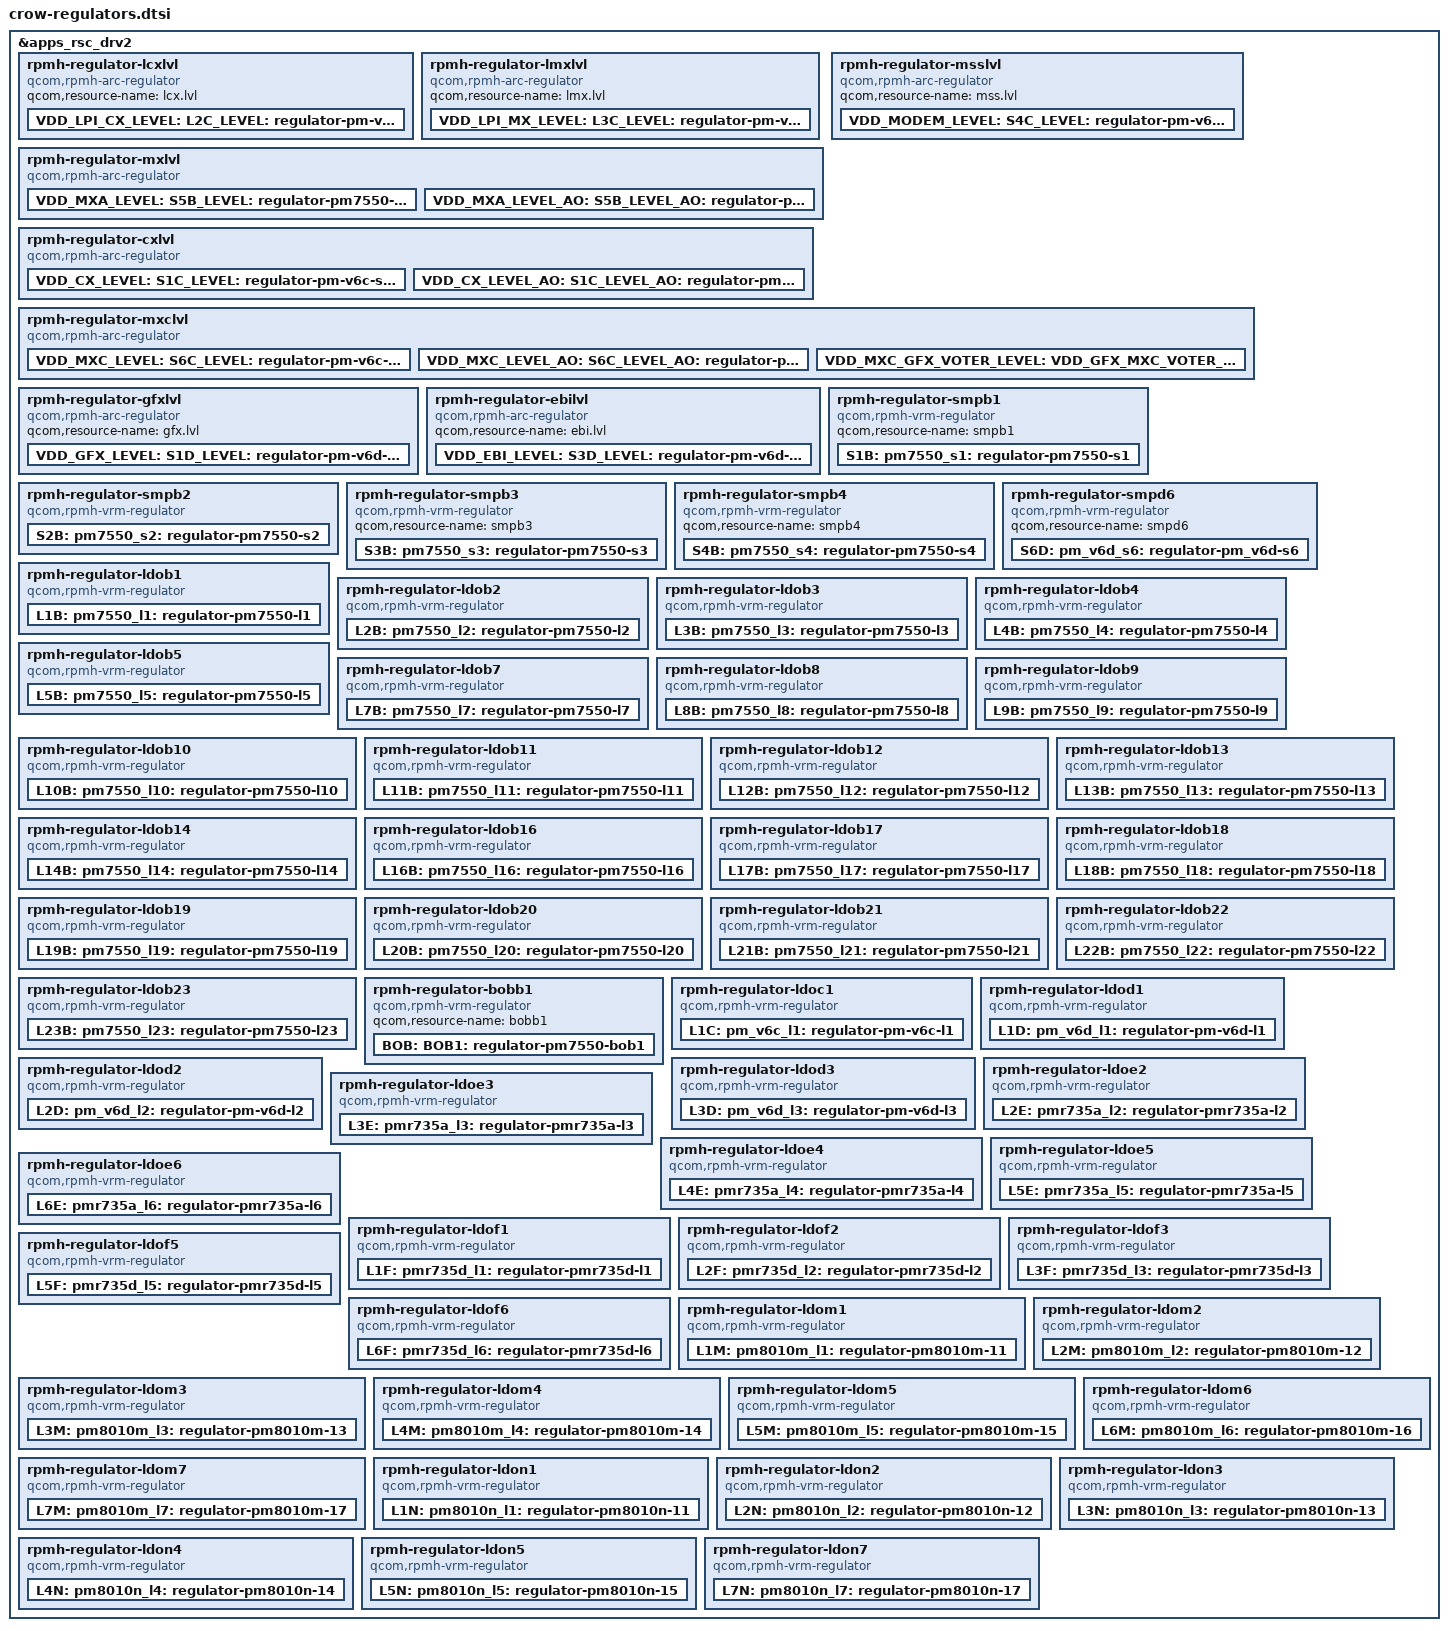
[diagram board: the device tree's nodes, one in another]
#include <dt-bindings/regulator/qcom,rpmh-regulator-levels.h>

&apps_rsc_drv2 {

	rpmh-regulator-lcxlvl {
		compatible = "qcom,rpmh-arc-regulator";
		qcom,resource-name = "lcx.lvl";

		VDD_LPI_CX_LEVEL: L2C_LEVEL:
		pm_v6c_l2_level: regulator-pm-v6c-l2-level {
			regulator-name = "pm_v6c_l2_level";
			qcom,set = <RPMH_REGULATOR_SET_ALL>;
			regulator-min-microvolt =
				<RPMH_REGULATOR_LEVEL_RETENTION>;
			regulator-max-microvolt =
				<RPMH_REGULATOR_LEVEL_MAX>;
			qcom,init-voltage-level =
				<RPMH_REGULATOR_LEVEL_RETENTION>;
		};
	};

	rpmh-regulator-lmxlvl {
		compatible = "qcom,rpmh-arc-regulator";
		qcom,resource-name = "lmx.lvl";

		VDD_LPI_MX_LEVEL: L3C_LEVEL:
		pm_v6c_l3_level: regulator-pm-v6c-l3-level {
			regulator-name = "pm_v6c_l3_level";
			qcom,set = <RPMH_REGULATOR_SET_ALL>;
			regulator-min-microvolt =
				<RPMH_REGULATOR_LEVEL_RETENTION>;
			regulator-max-microvolt =
				<RPMH_REGULATOR_LEVEL_MAX>;
			qcom,init-voltage-level =
				<RPMH_REGULATOR_LEVEL_RETENTION>;
		};
	};

	rpmh-regulator-mxlvl {
		compatible = "qcom,rpmh-arc-regulator";
		qcom,resource-name = "mx.lvl";
		proxy-supply = <&VDD_MXA_LEVEL>;

		VDD_MXA_LEVEL: S5B_LEVEL:
		pm7550_s5_level: regulator-pm7550-s5-level {
			regulator-name = "pm7550_s5_level";
			qcom,set = <RPMH_REGULATOR_SET_ALL>;
			regulator-min-microvolt =
				<RPMH_REGULATOR_LEVEL_RETENTION>;
			regulator-max-microvolt =
				<RPMH_REGULATOR_LEVEL_MAX>;
			qcom,init-voltage-level =
				<RPMH_REGULATOR_LEVEL_TURBO>;
			qcom,proxy-consumer-enable;
			qcom,proxy-consumer-voltage =
				<RPMH_REGULATOR_LEVEL_TURBO
				 RPMH_REGULATOR_LEVEL_MAX>;
		};

		VDD_MXA_LEVEL_AO: S5B_LEVEL_AO:
		pm7550_s5_level_ao: regulator-pm7750-s5-level-ao {
			regulator-name = "pm7550_s5_level_ao";
			qcom,set = <RPMH_REGULATOR_SET_ACTIVE>;
			regulator-min-microvolt =
				<RPMH_REGULATOR_LEVEL_RETENTION>;
			regulator-max-microvolt =
				<RPMH_REGULATOR_LEVEL_MAX>;
			qcom,init-voltage-level =
				<RPMH_REGULATOR_LEVEL_RETENTION>;
		};
	};

	rpmh-regulator-cxlvl {
		compatible = "qcom,rpmh-arc-regulator";
		qcom,resource-name = "cx.lvl";
		proxy-supply = <&VDD_CX_LEVEL>;

		VDD_CX_LEVEL: S1C_LEVEL:
		pm_v6c_s1_level: regulator-pm-v6c-s1-level {
			regulator-name = "pm_v6c_s1_level";
			qcom,set = <RPMH_REGULATOR_SET_ALL>;
			regulator-min-microvolt =
				<RPMH_REGULATOR_LEVEL_RETENTION>;
			regulator-max-microvolt =
				<RPMH_REGULATOR_LEVEL_MAX>;
			qcom,init-voltage-level =
				<RPMH_REGULATOR_LEVEL_TURBO>;
			qcom,proxy-consumer-enable;
			qcom,proxy-consumer-voltage =
				<RPMH_REGULATOR_LEVEL_TURBO
				 RPMH_REGULATOR_LEVEL_MAX>;
		};

		VDD_CX_LEVEL_AO: S1C_LEVEL_AO:
		pm_v6c_s1_level_ao: regulator-pm-v6c-s1-level-ao {
			regulator-name = "pm_v6c_s1_level_ao";
			qcom,set = <RPMH_REGULATOR_SET_ACTIVE>;
			regulator-min-microvolt =
				<RPMH_REGULATOR_LEVEL_RETENTION>;
			regulator-max-microvolt =
				<RPMH_REGULATOR_LEVEL_MAX>;
			qcom,init-voltage-level =
				<RPMH_REGULATOR_LEVEL_RETENTION>;
		};

	};

	rpmh-regulator-msslvl {
		compatible = "qcom,rpmh-arc-regulator";
		qcom,resource-name = "mss.lvl";

		VDD_MODEM_LEVEL: S4C_LEVEL:
		pm_v6c_s4_level: regulator-pm-v6c-s4-level {
			regulator-name = "pm_v6c_s4_level";
			qcom,set = <RPMH_REGULATOR_SET_ALL>;
			regulator-min-microvolt =
				<RPMH_REGULATOR_LEVEL_RETENTION>;
			regulator-max-microvolt =
				<RPMH_REGULATOR_LEVEL_MAX>;
			qcom,init-voltage-level =
				<RPMH_REGULATOR_LEVEL_RETENTION>;
		};
	};

	rpmh-regulator-mxclvl {
		compatible = "qcom,rpmh-arc-regulator";
		qcom,resource-name = "mxc.lvl";
		proxy-supply = <&VDD_MXC_LEVEL>;

		VDD_MXC_LEVEL: S6C_LEVEL:
		pm_v6c_s6_level: regulator-pm-v6c-s6-level {
			regulator-name = "pm_v6c_s6_level";
			qcom,set = <RPMH_REGULATOR_SET_ALL>;
			regulator-min-microvolt =
				<RPMH_REGULATOR_LEVEL_RETENTION>;
			regulator-max-microvolt =
				<RPMH_REGULATOR_LEVEL_MAX>;
			qcom,init-voltage-level =
				<RPMH_REGULATOR_LEVEL_TURBO>;
			qcom,proxy-consumer-enable;
			qcom,proxy-consumer-voltage =
				<RPMH_REGULATOR_LEVEL_TURBO
				 RPMH_REGULATOR_LEVEL_MAX>;
		};

		VDD_MXC_LEVEL_AO: S6C_LEVEL_AO:
		pm_v6c_s6_level_ao: regulator-pm-v6c-s6-level-ao {
			regulator-name = "pm_v6c_s6_level_ao";
			qcom,set = <RPMH_REGULATOR_SET_ACTIVE>;
			regulator-min-microvolt =
				<RPMH_REGULATOR_LEVEL_RETENTION>;
			regulator-max-microvolt =
				<RPMH_REGULATOR_LEVEL_MAX>;
			qcom,init-voltage-level =
				<RPMH_REGULATOR_LEVEL_RETENTION>;
		};

		VDD_MXC_GFX_VOTER_LEVEL: VDD_GFX_MXC_VOTER_LEVEL:
		regulator-pm-v6c-s6-gfx-voter-level {
			regulator-name = "pm_v6c_s6_gfx_voter_level";
			pm_v6c_s6_gfx_voter_level-parent-supply =
				<&VDD_GFX_LEVEL>;
			qcom,set = <RPMH_REGULATOR_SET_ALL>;
			regulator-min-microvolt =
				<RPMH_REGULATOR_LEVEL_MIN_SVS>;
			regulator-max-microvolt =
				<RPMH_REGULATOR_LEVEL_MAX>;
			qcom,init-voltage-level =
				<RPMH_REGULATOR_LEVEL_MIN_SVS>;
		};


	};

	rpmh-regulator-gfxlvl {
		compatible = "qcom,rpmh-arc-regulator";
		qcom,resource-name = "gfx.lvl";

		VDD_GFX_LEVEL: S1D_LEVEL:
		pm_v6d_s1_level: regulator-pm-v6d-s1-level {
			regulator-name = "pm_v6d_s1_level";
			qcom,set = <RPMH_REGULATOR_SET_ALL>;
			regulator-min-microvolt =
				<RPMH_REGULATOR_LEVEL_RETENTION>;
			regulator-max-microvolt =
				<RPMH_REGULATOR_LEVEL_MAX>;
			qcom,init-voltage-level =
				<RPMH_REGULATOR_LEVEL_RETENTION>;
		};
	};

	rpmh-regulator-ebilvl {
		compatible = "qcom,rpmh-arc-regulator";
		qcom,resource-name = "ebi.lvl";

		VDD_EBI_LEVEL: S3D_LEVEL:
		pm_v6d_s3_level: regulator-pm-v6d-s3-level {
			regulator-name = "pm_v6d_s3_level";
			qcom,set = <RPMH_REGULATOR_SET_ALL>;
			regulator-min-microvolt =
				<RPMH_REGULATOR_LEVEL_RETENTION>;
			regulator-max-microvolt =
				<RPMH_REGULATOR_LEVEL_MAX>;
			qcom,init-voltage-level =
				<RPMH_REGULATOR_LEVEL_RETENTION>;
		};
	};

	rpmh-regulator-smpb1 {
		compatible = "qcom,rpmh-vrm-regulator";
		qcom,resource-name = "smpb1";
		S1B: pm7550_s1: regulator-pm7550-s1 {
			regulator-name = "pm7550_s1";
			qcom,set = <RPMH_REGULATOR_SET_ALL>;
			regulator-min-microvolt = <1800000>;
			regulator-max-microvolt = <2040000>;
			qcom,init-voltage = <1872000>;
		};
	};

	rpmh-regulator-smpb2 {
		compatible = "qcom,rpmh-vrm-regulator";
		qcom,resource-name = "smpb2";
		qcom,regulator-type = "pmic5-ftsmps";
		qcom,supported-modes =
			<RPMH_REGULATOR_MODE_RET
			RPMH_REGULATOR_MODE_HPM>;
		qcom,mode-threshold-currents = <0 200000>;

		S2B: pm7550_s2: regulator-pm7550-s2 {
			regulator-name = "pm7550_s2";
			qcom,set = <RPMH_REGULATOR_SET_ALL>;
			regulator-min-microvolt = <1256000>;
			regulator-max-microvolt = <1408000>;
			qcom,init-voltage = <1304000>;
			qcom,init-mode = <RPMH_REGULATOR_MODE_RET>;
		};
	};

	rpmh-regulator-smpb3 {
		compatible = "qcom,rpmh-vrm-regulator";
		qcom,resource-name = "smpb3";
		S3B: pm7550_s3: regulator-pm7550-s3 {
			regulator-name = "pm7550_s3";
			qcom,set = <RPMH_REGULATOR_SET_ALL>;
			regulator-min-microvolt = <880000>;
			regulator-max-microvolt = <1040000>;
			qcom,init-voltage = <972000>;
		};
	};

	rpmh-regulator-smpb4 {
		compatible = "qcom,rpmh-vrm-regulator";
		qcom,resource-name = "smpb4";
		S4B: pm7550_s4: regulator-pm7550-s4 {
			regulator-name = "pm7550_s4";
			qcom,set = <RPMH_REGULATOR_SET_ALL>;
			regulator-min-microvolt = <2200000>;
			regulator-max-microvolt = <2200000>;
			qcom,init-voltage = <2200000>;
		};
	};

	rpmh-regulator-smpd6 {
		compatible = "qcom,rpmh-vrm-regulator";
		qcom,resource-name = "smpd6";
		S6D: pm_v6d_s6: regulator-pm_v6d-s6 {
			regulator-name = "pm_v6d_s6";
			qcom,set = <RPMH_REGULATOR_SET_ALL>;
			regulator-min-microvolt = <1010000>;
			regulator-max-microvolt = <1170000>;
			qcom,init-voltage = <1010000>;
		};
	};

	rpmh-regulator-ldob1 {
		compatible = "qcom,rpmh-vrm-regulator";
		qcom,resource-name = "ldob1";
		qcom,regulator-type = "pmic5-ldo";
		qcom,supported-modes =
			<RPMH_REGULATOR_MODE_LPM
			RPMH_REGULATOR_MODE_HPM>;
		qcom,mode-threshold-currents = <0 30000>;
		L1B:
		pm7550_l1: regulator-pm7550-l1 {
			regulator-name = "pm7550_l1";
			qcom,set = <RPMH_REGULATOR_SET_ALL>;
			regulator-min-microvolt = <880000>;
			regulator-max-microvolt = <912000>;
			qcom,init-voltage = <880000>;
			qcom,init-mode = <RPMH_REGULATOR_MODE_HPM>;
		};
	};

	rpmh-regulator-ldob2 {
		compatible = "qcom,rpmh-vrm-regulator";
		qcom,resource-name = "ldob2";
		qcom,regulator-type = "pmic5-ldo";
		qcom,supported-modes =
			<RPMH_REGULATOR_MODE_LPM
			RPMH_REGULATOR_MODE_HPM>;
		qcom,mode-threshold-currents = <0 30000>;
		proxy-supply = <&L2B>;

		L2B:
		pm7550_l2: regulator-pm7550-l2 {
			regulator-name = "pm7550_l2";
			qcom,set = <RPMH_REGULATOR_SET_ALL>;
			regulator-min-microvolt = <880000>;
			regulator-max-microvolt = <912000>;
			qcom,init-voltage = <880000>;
			qcom,init-mode = <RPMH_REGULATOR_MODE_HPM>;
			qcom,proxy-consumer-enable;
			qcom,proxy-consumer-current = <98400>;
		};
	};

	rpmh-regulator-ldob3 {
		compatible = "qcom,rpmh-vrm-regulator";
		qcom,resource-name = "ldob3";
		qcom,regulator-type = "pmic5-ldo";
		qcom,supported-modes =
			<RPMH_REGULATOR_MODE_LPM
			RPMH_REGULATOR_MODE_HPM>;
		qcom,mode-threshold-currents = <0 30000>;
		L3B:
		pm7550_l3: regulator-pm7550-l3 {
			regulator-name = "pm7550_l3";
			qcom,set = <RPMH_REGULATOR_SET_ALL>;
			regulator-min-microvolt = <880000>;
			regulator-max-microvolt = <912000>;
			qcom,init-voltage = <880000>;
			qcom,init-mode = <RPMH_REGULATOR_MODE_HPM>;
		};
	};

	rpmh-regulator-ldob4 {
		compatible = "qcom,rpmh-vrm-regulator";
		qcom,resource-name = "ldob4";
		qcom,regulator-type = "pmic5-ldo";
		qcom,supported-modes =
			<RPMH_REGULATOR_MODE_LPM
			RPMH_REGULATOR_MODE_HPM>;
		qcom,mode-threshold-currents = <0 30000>;
		proxy-supply = <&L4B>;

		L4B:
		pm7550_l4: regulator-pm7550-l4 {
			regulator-name = "pm7550_l4";
			qcom,set = <RPMH_REGULATOR_SET_ALL>;
			regulator-min-microvolt = <1200000>;
			regulator-max-microvolt = <1200000>;
			qcom,init-voltage = <1200000>;
			qcom,init-mode = <RPMH_REGULATOR_MODE_HPM>;
			qcom,proxy-consumer-enable;
			qcom,proxy-consumer-current = <16800>;
		};
	};

	rpmh-regulator-ldob5 {
		compatible = "qcom,rpmh-vrm-regulator";
		qcom,resource-name = "ldob5";
		qcom,regulator-type = "pmic5-ldo";
		qcom,supported-modes =
			<RPMH_REGULATOR_MODE_RET
			RPMH_REGULATOR_MODE_LPM
			RPMH_REGULATOR_MODE_HPM>;
		qcom,mode-threshold-currents = <0 10000 30000>;
		L5B:
		pm7550_l5: regulator-pm7550-l5 {
			regulator-name = "pm7550_l5";
			qcom,set = <RPMH_REGULATOR_SET_ALL>;
			regulator-min-microvolt = <1200000>;
			regulator-max-microvolt = <1200000>;
			qcom,init-voltage = <1200000>;
			qcom,init-mode = <RPMH_REGULATOR_MODE_HPM>;
		};
	};

	rpmh-regulator-ldob7 {
		compatible = "qcom,rpmh-vrm-regulator";
		qcom,resource-name = "ldob7";
		qcom,regulator-type = "pmic5-ldo";
		qcom,supported-modes =
			<RPMH_REGULATOR_MODE_LPM
			RPMH_REGULATOR_MODE_HPM>;
		qcom,mode-threshold-currents = <0 30000>;
		L7B:
		pm7550_l7: regulator-pm7550-l7 {
			regulator-name = "pm7550_l7";
			qcom,set = <RPMH_REGULATOR_SET_ALL>;
			regulator-min-microvolt = <1800000>;
			regulator-max-microvolt = <1800000>;
			qcom,init-voltage = <1800000>;
			qcom,init-mode = <RPMH_REGULATOR_MODE_HPM>;
		};
	};

	rpmh-regulator-ldob8 {
		compatible = "qcom,rpmh-vrm-regulator";
		qcom,resource-name = "ldob8";
		qcom,regulator-type = "pmic5-ldo";
		qcom,supported-modes =
			<RPMH_REGULATOR_MODE_LPM
			RPMH_REGULATOR_MODE_HPM>;
		qcom,mode-threshold-currents = <0 30000>;
		L8B:
		pm7550_l8: regulator-pm7550-l8 {
			regulator-name = "pm7550_l8";
			qcom,set = <RPMH_REGULATOR_SET_ALL>;
			regulator-min-microvolt = <1800000>;
			regulator-max-microvolt = <1800000>;
			qcom,init-voltage = <1800000>;
			qcom,init-mode = <RPMH_REGULATOR_MODE_HPM>;
		};
	};

	rpmh-regulator-ldob9 {
		compatible = "qcom,rpmh-vrm-regulator";
		qcom,resource-name = "ldob9";
		qcom,regulator-type = "pmic5-ldo";
		qcom,supported-modes =
			<RPMH_REGULATOR_MODE_LPM
			RPMH_REGULATOR_MODE_HPM>;
		qcom,mode-threshold-currents = <0 30000>;
		proxy-supply = <&L9B>;

		L9B:
		pm7550_l9: regulator-pm7550-l9 {
			regulator-name = "pm7550_l9";
			qcom,set = <RPMH_REGULATOR_SET_ALL>;
			regulator-min-microvolt = <1800000>;
			regulator-max-microvolt = <1800000>;
			qcom,init-voltage = <1800000>;
			qcom,init-mode = <RPMH_REGULATOR_MODE_HPM>;
			qcom,proxy-consumer-enable;
			qcom,proxy-consumer-current = <200000>;
		};
	};

	rpmh-regulator-ldob10 {
		compatible = "qcom,rpmh-vrm-regulator";
		qcom,resource-name = "ldob10";
		qcom,regulator-type = "pmic5-ldo";
		qcom,supported-modes =
			<RPMH_REGULATOR_MODE_LPM
			RPMH_REGULATOR_MODE_HPM>;
		qcom,mode-threshold-currents = <0 30000>;
		L10B:
		pm7550_l10: regulator-pm7550-l10 {
			regulator-name = "pm7550_l10";
			qcom,set = <RPMH_REGULATOR_SET_ALL>;
			regulator-min-microvolt = <1800000>;
			regulator-max-microvolt = <1800000>;
			qcom,init-voltage = <1800000>;
			qcom,init-mode = <RPMH_REGULATOR_MODE_HPM>;
		};
	};

	rpmh-regulator-ldob11 {
		compatible = "qcom,rpmh-vrm-regulator";
		qcom,resource-name = "ldob11";
		qcom,regulator-type = "pmic5-ldo";
		qcom,supported-modes =
			<RPMH_REGULATOR_MODE_LPM
			RPMH_REGULATOR_MODE_HPM>;
		qcom,mode-threshold-currents = <0 30000>;
		L11B:
		pm7550_l11: regulator-pm7550-l11 {
			regulator-name = "pm7550_l11";
			qcom,set = <RPMH_REGULATOR_SET_ALL>;
			regulator-min-microvolt = <1800000>;
			regulator-max-microvolt = <1800000>;
			qcom,init-voltage = <1800000>;
			qcom,init-mode = <RPMH_REGULATOR_MODE_HPM>;
		};
	};

	rpmh-regulator-ldob12 {
		compatible = "qcom,rpmh-vrm-regulator";
		qcom,resource-name = "ldob12";
		qcom,regulator-type = "pmic5-ldo";
		qcom,supported-modes =
			<RPMH_REGULATOR_MODE_LPM
			RPMH_REGULATOR_MODE_HPM>;
		qcom,mode-threshold-currents = <0 10000>;
		/*This is for UFS Peripheral,which supports 2 variants*/
		/*UFS 3.1 ,and UFS 2.2 both require different voltages.*/
		/* Hence Not providing voltage values as per previous targets*/
		L12B:
		pm7550_l12: regulator-pm7550-l12 {
			regulator-name = "pm7550_l12";
			qcom,set = <RPMH_REGULATOR_SET_ALL>;
			qcom,init-mode = <RPMH_REGULATOR_MODE_HPM>;
		};
	};

	rpmh-regulator-ldob13 {
		compatible = "qcom,rpmh-vrm-regulator";
		qcom,resource-name = "ldob13";
		qcom,regulator-type = "pmic5-ldo";
		qcom,supported-modes =
			<RPMH_REGULATOR_MODE_LPM
			RPMH_REGULATOR_MODE_HPM>;
		qcom,mode-threshold-currents = <0 10000>;
		L13B:
		pm7550_l13: regulator-pm7550-l13 {
			regulator-name = "pm7550_l13";
			qcom,set = <RPMH_REGULATOR_SET_ALL>;
			regulator-min-microvolt = <2700000>;
			regulator-max-microvolt = <3300000>;
			qcom,init-voltage = <2700000>;
			qcom,init-mode = <RPMH_REGULATOR_MODE_HPM>;
		};
	};

	rpmh-regulator-ldob14 {
		compatible = "qcom,rpmh-vrm-regulator";
		qcom,resource-name = "ldob14";
		qcom,regulator-type = "pmic5-ldo";
		qcom,supported-modes =
			<RPMH_REGULATOR_MODE_LPM
			RPMH_REGULATOR_MODE_HPM>;
		qcom,mode-threshold-currents = <0 10000>;
		L14B:
		pm7550_l14: regulator-pm7550-l14 {
			regulator-name = "pm7550_l14";
			qcom,set = <RPMH_REGULATOR_SET_ALL>;
			regulator-min-microvolt = <2650000>;
			regulator-max-microvolt = <2940000>;
			qcom,init-voltage = <2650000>;
			qcom,init-mode = <RPMH_REGULATOR_MODE_HPM>;
		};
	};

	rpmh-regulator-ldob16 {
		compatible = "qcom,rpmh-vrm-regulator";
		qcom,resource-name = "ldob16";
		qcom,regulator-type = "pmic5-ldo";
		qcom,supported-modes =
			<RPMH_REGULATOR_MODE_LPM
			RPMH_REGULATOR_MODE_HPM>;
		qcom,mode-threshold-currents = <0 10000>;
		L16B:
		pm7550_l16: regulator-pm7550-l16 {
			regulator-name = "pm7550_l16";
			qcom,set = <RPMH_REGULATOR_SET_ALL>;
			regulator-min-microvolt = <3008000>;
			regulator-max-microvolt = <3008000>;
			qcom,init-voltage = <3008000>;
			qcom,init-mode = <RPMH_REGULATOR_MODE_HPM>;
		};
	};

	rpmh-regulator-ldob17 {
		compatible = "qcom,rpmh-vrm-regulator";
		qcom,resource-name = "ldob17";
		qcom,regulator-type = "pmic5-ldo";
		qcom,supported-modes =
			<RPMH_REGULATOR_MODE_LPM
			RPMH_REGULATOR_MODE_HPM>;
		qcom,mode-threshold-currents = <0 10000>;
		L17B:
		pm7550_l17: regulator-pm7550-l17 {
			regulator-name = "pm7550_l17";
			qcom,set = <RPMH_REGULATOR_SET_ALL>;
			regulator-min-microvolt = <3104000>;
			regulator-max-microvolt = <3104000>;
			qcom,init-voltage = <3104000>;
			qcom,init-mode = <RPMH_REGULATOR_MODE_HPM>;
		};
	};

	rpmh-regulator-ldob18 {
		compatible = "qcom,rpmh-vrm-regulator";
		qcom,resource-name = "ldob18";
		qcom,regulator-type = "pmic5-ldo";
		qcom,supported-modes =
			<RPMH_REGULATOR_MODE_LPM
			RPMH_REGULATOR_MODE_HPM>;
		qcom,mode-threshold-currents = <0 10000>;
		L18B:
		pm7550_l18: regulator-pm7550-l18 {
			regulator-name = "pm7550_l18";
			qcom,set = <RPMH_REGULATOR_SET_ALL>;
			regulator-min-microvolt = <2800000>;
			regulator-max-microvolt = <2800000>;
			qcom,init-voltage = <2800000>;
			qcom,init-mode = <RPMH_REGULATOR_MODE_HPM>;
		};
	};

	rpmh-regulator-ldob19 {
		compatible = "qcom,rpmh-vrm-regulator";
		qcom,resource-name = "ldob19";
		qcom,regulator-type = "pmic5-ldo";
		qcom,supported-modes =
			<RPMH_REGULATOR_MODE_LPM
			RPMH_REGULATOR_MODE_HPM>;
		qcom,mode-threshold-currents = <0 10000>;
		proxy-supply = <&L19B>;

		L19B:
		pm7550_l19: regulator-pm7550-l19 {
			regulator-name = "pm7550_l19";
			qcom,set = <RPMH_REGULATOR_SET_ALL>;
			regulator-min-microvolt = <3000000>;
			regulator-max-microvolt = <3000000>;
			qcom,init-voltage = <3000000>;
			qcom,init-mode = <RPMH_REGULATOR_MODE_HPM>;
			qcom,proxy-consumer-enable;
			qcom,proxy-consumer-current = <10000>;
		};
	};

	rpmh-regulator-ldob20 {
		compatible = "qcom,rpmh-vrm-regulator";
		qcom,resource-name = "ldob20";
		qcom,regulator-type = "pmic5-ldo";
		qcom,supported-modes =
			<RPMH_REGULATOR_MODE_LPM
			RPMH_REGULATOR_MODE_HPM>;
		qcom,mode-threshold-currents = <0 10000>;
		L20B:
		pm7550_l20: regulator-pm7550-l20 {
			regulator-name = "pm7550_l20";
			qcom,set = <RPMH_REGULATOR_SET_ALL>;
			regulator-min-microvolt = <1620000>;
			regulator-max-microvolt = <3544000>;
			qcom,init-voltage = <1620000>;
			qcom,init-mode = <RPMH_REGULATOR_MODE_HPM>;
		};
	};

	rpmh-regulator-ldob21 {
		compatible = "qcom,rpmh-vrm-regulator";
		qcom,resource-name = "ldob21";
		qcom,regulator-type = "pmic5-ldo";
		qcom,supported-modes =
			<RPMH_REGULATOR_MODE_LPM
			RPMH_REGULATOR_MODE_HPM>;
		qcom,mode-threshold-currents = <0 10000>;
		L21B:
		pm7550_l21: regulator-pm7550-l21 {
			regulator-name = "pm7550_l21";
			qcom,set = <RPMH_REGULATOR_SET_ALL>;
			regulator-min-microvolt = <1620000>;
			regulator-max-microvolt = <3544000>;
			qcom,init-voltage = <1620000>;
			qcom,init-mode = <RPMH_REGULATOR_MODE_HPM>;
		};
	};

	rpmh-regulator-ldob22 {
		compatible = "qcom,rpmh-vrm-regulator";
		qcom,resource-name = "ldob22";
		qcom,regulator-type = "pmic5-ldo";
		qcom,supported-modes =
			<RPMH_REGULATOR_MODE_LPM
			RPMH_REGULATOR_MODE_HPM>;
		qcom,mode-threshold-currents = <0 10000>;
		L22B:
		pm7550_l22: regulator-pm7550-l22 {
			regulator-name = "pm7550_l22";
			qcom,set = <RPMH_REGULATOR_SET_ALL>;
			regulator-min-microvolt = <3200000>;
			regulator-max-microvolt = <3200000>;
			qcom,init-voltage = <3200000>;
			qcom,init-mode = <RPMH_REGULATOR_MODE_HPM>;
		};
	};

	rpmh-regulator-ldob23 {
		compatible = "qcom,rpmh-vrm-regulator";
		qcom,resource-name = "ldob23";
		qcom,regulator-type = "pmic5-ldo";
		qcom,supported-modes =
			<RPMH_REGULATOR_MODE_LPM
			RPMH_REGULATOR_MODE_HPM>;
		qcom,mode-threshold-currents = <0 10000>;
		L23B:
		pm7550_l23: regulator-pm7550-l23 {
			regulator-name = "pm7550_l23";
			qcom,set = <RPMH_REGULATOR_SET_ALL>;
			regulator-min-microvolt = <1650000>;
			regulator-max-microvolt = <3544000>;
			qcom,init-voltage = <1650000>;
			qcom,init-mode = <RPMH_REGULATOR_MODE_HPM>;
		};
	};

	rpmh-regulator-bobb1 {
		compatible = "qcom,rpmh-vrm-regulator";
		qcom,resource-name = "bobb1";

		BOB:
		BOB1:
		pm7550_bob1: regulator-pm7550-bob1 {
			regulator-name = "pm7550_bob1";
			qcom,set = <RPMH_REGULATOR_SET_ALL>;
			regulator-min-microvolt = <3008000>;
			regulator-max-microvolt = <3960000>;
			qcom,init-voltage = <3296000>;
		};
	};

	rpmh-regulator-ldoc1 {
		compatible = "qcom,rpmh-vrm-regulator";
		qcom,resource-name = "ldoc1";
		qcom,regulator-type = "pmic5-ldo";
		qcom,supported-modes =
			<RPMH_REGULATOR_MODE_LPM
			RPMH_REGULATOR_MODE_HPM>;
		qcom,mode-threshold-currents = <0 30000>;
		L1C:
		pm_v6c_l1: regulator-pm-v6c-l1 {
			regulator-name = "pm_v6c_l1";
			qcom,set = <RPMH_REGULATOR_SET_ALL>;
			regulator-min-microvolt = <320000>;
			regulator-max-microvolt = <650000>;
			qcom,init-voltage = <300000>;
			qcom,init-mode = <RPMH_REGULATOR_MODE_HPM>;
		};
	};

	rpmh-regulator-ldod1 {
		compatible = "qcom,rpmh-vrm-regulator";
		qcom,resource-name = "ldod1";
		qcom,regulator-type = "pmic5-ldo";
		qcom,supported-modes =
			<RPMH_REGULATOR_MODE_LPM
			 RPMH_REGULATOR_MODE_HPM>;
		qcom,mode-threshold-currents = <0 30000>;

		L1D:
		pm_v6d_l1: regulator-pm-v6d-l1 {
			regulator-name = "pm_v6d_l1";
			qcom,set = <RPMH_REGULATOR_SET_ALL>;
			regulator-min-microvolt = <870000>;
			regulator-max-microvolt = <970000>;
			qcom,init-voltage = <904000>;
			qcom,init-mode = <RPMH_REGULATOR_MODE_HPM>;
		};
	};

	rpmh-regulator-ldod2 {
		compatible = "qcom,rpmh-vrm-regulator";
		qcom,resource-name = "ldod2";
		qcom,regulator-type = "pmic5-ldo";
		qcom,supported-modes =
			<RPMH_REGULATOR_MODE_LPM
			 RPMH_REGULATOR_MODE_HPM>;
		qcom,mode-threshold-currents = <0 30000>;

		/*This is for UFS Peripheral,which supports 2 variants*/
		/*UFS 3.1 ,and UFS 2.2 both require different voltages.*/
		/* Hence Not providing voltage values as per previous targets*/
		L2D:
		pm_v6d_l2: regulator-pm-v6d-l2 {
			regulator-name = "pm_v6d_l2";
			qcom,set = <RPMH_REGULATOR_SET_ALL>;
			qcom,init-mode = <RPMH_REGULATOR_MODE_HPM>;
		};
	};

	rpmh-regulator-ldod3 {
		compatible = "qcom,rpmh-vrm-regulator";
		qcom,resource-name = "ldod3";
		qcom,regulator-type = "pmic5-ldo";
		qcom,supported-modes =
			<RPMH_REGULATOR_MODE_LPM
			 RPMH_REGULATOR_MODE_HPM>;
		qcom,mode-threshold-currents = <0 30000>;
		proxy-supply = <&L3D>;

		L3D:
		pm_v6d_l3: regulator-pm-v6d-l3 {
			regulator-name = "pm_v6d_l3";
			qcom,set = <RPMH_REGULATOR_SET_ALL>;
			regulator-min-microvolt = <1200000>;
			regulator-max-microvolt = <1200000>;
			qcom,init-voltage = <1200000>;
			qcom,init-mode = <RPMH_REGULATOR_MODE_HPM>;
			qcom,proxy-consumer-enable;
			qcom,proxy-consumer-current = <299000>;
		};
	};

	rpmh-regulator-ldoe2 {
		compatible = "qcom,rpmh-vrm-regulator";
		qcom,resource-name = "ldoe2";
		qcom,regulator-type = "pmic5-ldo";
		qcom,supported-modes =
			<RPMH_REGULATOR_MODE_LPM
			 RPMH_REGULATOR_MODE_HPM>;
		qcom,mode-threshold-currents = <0 30000>;
		L2E:
		pmr735a_l2: regulator-pmr735a-l2 {
			regulator-name = "pmr735a_l2";
			qcom,set = <RPMH_REGULATOR_SET_ALL>;
			regulator-min-microvolt = <800000>;
			regulator-max-microvolt = <800000>;
			qcom,init-voltage = <800000>;
			qcom,init-mode = <RPMH_REGULATOR_MODE_HPM>;
		};
	};

	rpmh-regulator-ldoe3 {
		compatible = "qcom,rpmh-vrm-regulator";
		qcom,resource-name = "ldoe3";
		qcom,regulator-type = "pmic5-ldo";
		qcom,supported-modes =
			<RPMH_REGULATOR_MODE_LPM
			 RPMH_REGULATOR_MODE_HPM>;
		qcom,mode-threshold-currents = <0 30000>;
		L3E:
		pmr735a_l3: regulator-pmr735a-l3 {
			regulator-name = "pmr735a_l3";
			qcom,set = <RPMH_REGULATOR_SET_ALL>;
			regulator-min-microvolt = <588000>;
			regulator-max-microvolt = <800000>;
			qcom,init-voltage = <588000>;
			qcom,init-mode = <RPMH_REGULATOR_MODE_HPM>;
		};
	};

	rpmh-regulator-ldoe4 {
		compatible = "qcom,rpmh-vrm-regulator";
		qcom,resource-name = "ldoe4";
		qcom,regulator-type = "pmic5-ldo";
		qcom,supported-modes =
			<RPMH_REGULATOR_MODE_LPM
			 RPMH_REGULATOR_MODE_HPM>;
		qcom,mode-threshold-currents = <0 10000>;
		L4E:
		pmr735a_l4: regulator-pmr735a-l4 {
			regulator-name = "pmr735a_l4";
			qcom,set = <RPMH_REGULATOR_SET_ALL>;
			regulator-min-microvolt = <1776000>;
			regulator-max-microvolt = <1776000>;
			qcom,init-voltage = <1776000>;
			qcom,init-mode = <RPMH_REGULATOR_MODE_HPM>;
		};
	};

	rpmh-regulator-ldoe5 {
		compatible = "qcom,rpmh-vrm-regulator";
		qcom,resource-name = "ldoe5";
		qcom,regulator-type = "pmic5-ldo";
		qcom,supported-modes =
			<RPMH_REGULATOR_MODE_LPM
			 RPMH_REGULATOR_MODE_HPM>;
		qcom,mode-threshold-currents = <0 30000>;
		L5E:
		pmr735a_l5: regulator-pmr735a-l5 {
			regulator-name = "pmr735a_l5";
			qcom,set = <RPMH_REGULATOR_SET_ALL>;
			regulator-min-microvolt = <1200000>;
			regulator-max-microvolt = <1200000>;
			qcom,init-voltage = <1200000>;
			qcom,init-mode = <RPMH_REGULATOR_MODE_HPM>;
		};
	};

	rpmh-regulator-ldoe6 {
		compatible = "qcom,rpmh-vrm-regulator";
		qcom,resource-name = "ldoe6";
		qcom,regulator-type = "pmic5-ldo";
		qcom,supported-modes =
			<RPMH_REGULATOR_MODE_LPM
			 RPMH_REGULATOR_MODE_HPM>;
		qcom,mode-threshold-currents = <0 30000>;
		L6E:
		pmr735a_l6: regulator-pmr735a-l6 {
			regulator-name = "pmr735a_l6";
			qcom,set = <RPMH_REGULATOR_SET_ALL>;
			regulator-min-microvolt = <880000>;
			regulator-max-microvolt = <912000>;
			qcom,init-voltage = <880000>;
			qcom,init-mode = <RPMH_REGULATOR_MODE_HPM>;
		};
	};

	rpmh-regulator-ldof1 {
		compatible = "qcom,rpmh-vrm-regulator";
		qcom,resource-name = "ldof1";
		qcom,regulator-type = "pmic5-ldo";
		qcom,supported-modes =
			<RPMH_REGULATOR_MODE_LPM
			 RPMH_REGULATOR_MODE_HPM>;
		qcom,mode-threshold-currents = <0 30000>;
		L1F:
		pmr735d_l1: regulator-pmr735d-l1 {
			regulator-name = "pmr735d_l1";
			qcom,set = <RPMH_REGULATOR_SET_ALL>;
			regulator-min-microvolt = <852000>;
			regulator-max-microvolt = <950000>;
			qcom,init-voltage = <852000>;
			qcom,init-mode = <RPMH_REGULATOR_MODE_HPM>;
		};
	};

	rpmh-regulator-ldof2 {
		compatible = "qcom,rpmh-vrm-regulator";
		qcom,resource-name = "ldof2";
		qcom,regulator-type = "pmic5-ldo";
		qcom,supported-modes =
			<RPMH_REGULATOR_MODE_LPM
			 RPMH_REGULATOR_MODE_HPM>;
		qcom,mode-threshold-currents = <0 30000>;
		L2F:
		pmr735d_l2: regulator-pmr735d-l2 {
			regulator-name = "pmr735d_l2";
			qcom,set = <RPMH_REGULATOR_SET_ALL>;
			regulator-min-microvolt = <320000>;
			regulator-max-microvolt = <864000>;
			qcom,init-voltage = <304000>;
			qcom,init-mode = <RPMH_REGULATOR_MODE_HPM>;
		};
	};

	rpmh-regulator-ldof3 {
		compatible = "qcom,rpmh-vrm-regulator";
		qcom,resource-name = "ldof3";
		qcom,regulator-type = "pmic5-ldo";
		qcom,supported-modes =
			<RPMH_REGULATOR_MODE_LPM
			 RPMH_REGULATOR_MODE_HPM>;
		qcom,mode-threshold-currents = <0 30000>;
		L3F:
		pmr735d_l3: regulator-pmr735d-l3 {
			regulator-name = "pmr735d_l3";
			qcom,set = <RPMH_REGULATOR_SET_ALL>;
			regulator-min-microvolt = <1080000>;
			regulator-max-microvolt = <1350000>;
			qcom,init-voltage = <108000>;
			qcom,init-mode = <RPMH_REGULATOR_MODE_HPM>;
		};
	};

	rpmh-regulator-ldof5 {
		compatible = "qcom,rpmh-vrm-regulator";
		qcom,resource-name = "ldof5";
		qcom,regulator-type = "pmic5-ldo";
		qcom,supported-modes =
			<RPMH_REGULATOR_MODE_LPM
			 RPMH_REGULATOR_MODE_HPM>;
		qcom,mode-threshold-currents = <0 30000>;
		L5F:
		pmr735d_l5: regulator-pmr735d-l5 {
			regulator-name = "pmr735d_l5";
			qcom,set = <RPMH_REGULATOR_SET_ALL>;
			regulator-min-microvolt = <751000>;
			regulator-max-microvolt = <824000>;
			qcom,init-voltage = <751000>;
			qcom,init-mode = <RPMH_REGULATOR_MODE_HPM>;
		};
	};

	rpmh-regulator-ldof6 {
		compatible = "qcom,rpmh-vrm-regulator";
		qcom,resource-name = "ldof6";
		qcom,regulator-type = "pmic5-ldo";
		qcom,supported-modes =
			<RPMH_REGULATOR_MODE_LPM
			 RPMH_REGULATOR_MODE_HPM>;
		qcom,mode-threshold-currents = <0 30000>;
		L6F:
		pmr735d_l6: regulator-pmr735d-l6 {
			regulator-name = "pmr735d_l6";
			qcom,set = <RPMH_REGULATOR_SET_ALL>;
			regulator-min-microvolt = <1500000>;
			regulator-max-microvolt = <1800000>;
			qcom,init-voltage = <1500000>;
			qcom,init-mode = <RPMH_REGULATOR_MODE_HPM>;
		};
	};

	rpmh-regulator-ldom1 {
		compatible = "qcom,rpmh-vrm-regulator";
		qcom,resource-name = "ldom1";
		qcom,regulator-type = "pmic5-ldo";
		qcom,supported-modes =
			<RPMH_REGULATOR_MODE_LPM
			 RPMH_REGULATOR_MODE_HPM>;
		qcom,mode-threshold-currents = <0 30000>;

		L1M:
		pm8010m_l1: regulator-pm8010m-11 {
			regulator-name = "pm8010m_l1";
			qcom,set = <RPMH_REGULATOR_SET_ALL>;
			regulator-min-microvolt = <1050000>;
			regulator-max-microvolt = <1180000>;
			qcom,init-voltage = <1050000>;
			qcom,init-mode = <RPMH_REGULATOR_MODE_HPM>;
		};
	};

	rpmh-regulator-ldom2 {
		compatible = "qcom,rpmh-vrm-regulator";
		qcom,resource-name = "ldom2";
		qcom,regulator-type = "pmic5-ldo";
		qcom,supported-modes =
			<RPMH_REGULATOR_MODE_LPM
			 RPMH_REGULATOR_MODE_HPM>;
		qcom,mode-threshold-currents = <0 30000>;

		L2M:
		pm8010m_l2: regulator-pm8010m-12 {
			regulator-name = "pm8010m_l2";
			qcom,set = <RPMH_REGULATOR_SET_ALL>;
			regulator-min-microvolt = <950000>;
			regulator-max-microvolt = <1150000>;
			qcom,init-voltage = <950000>;
			qcom,init-mode = <RPMH_REGULATOR_MODE_HPM>;
		};
	};

	rpmh-regulator-ldom3 {
		compatible = "qcom,rpmh-vrm-regulator";
		qcom,resource-name = "ldom3";
		qcom,regulator-type = "pmic5-ldo";
		qcom,supported-modes =
			<RPMH_REGULATOR_MODE_LPM
			 RPMH_REGULATOR_MODE_HPM>;
		qcom,mode-threshold-currents = <0 10000>;

		L3M:
		pm8010m_l3: regulator-pm8010m-13 {
			regulator-name = "pm8010m_l3";
			qcom,set = <RPMH_REGULATOR_SET_ALL>;
			regulator-min-microvolt = <2700000>;
			regulator-max-microvolt = <2900000>;
			qcom,init-voltage = <2700000>;
			qcom,init-mode = <RPMH_REGULATOR_MODE_HPM>;
		};
	};

	rpmh-regulator-ldom4 {
		compatible = "qcom,rpmh-vrm-regulator";
		qcom,resource-name = "ldom4";
		qcom,regulator-type = "pmic5-ldo";
		qcom,supported-modes =
			<RPMH_REGULATOR_MODE_LPM
			 RPMH_REGULATOR_MODE_HPM>;
		qcom,mode-threshold-currents = <0 10000>;

		L4M:
		pm8010m_l4: regulator-pm8010m-14 {
			regulator-name = "pm8010m_l4";
			qcom,set = <RPMH_REGULATOR_SET_ALL>;
			regulator-min-microvolt = <2700000>;
			regulator-max-microvolt = <2900000>;
			qcom,init-voltage = <2700000>;
			qcom,init-mode = <RPMH_REGULATOR_MODE_HPM>;
		};
	};

	rpmh-regulator-ldom5 {
		compatible = "qcom,rpmh-vrm-regulator";
		qcom,resource-name = "ldom5";
		qcom,regulator-type = "pmic5-ldo";
		qcom,supported-modes =
			<RPMH_REGULATOR_MODE_LPM
			 RPMH_REGULATOR_MODE_HPM>;
		qcom,mode-threshold-currents = <0 10000>;

		L5M:
		pm8010m_l5: regulator-pm8010m-15 {
			regulator-name = "pm8010m_l5";
			qcom,set = <RPMH_REGULATOR_SET_ALL>;
			regulator-min-microvolt = <1700000>;
			regulator-max-microvolt = <1900000>;
			qcom,init-voltage = <1700000>;
			qcom,init-mode = <RPMH_REGULATOR_MODE_HPM>;
		};
	};

	rpmh-regulator-ldom6 {
		compatible = "qcom,rpmh-vrm-regulator";
		qcom,resource-name = "ldom6";
		qcom,regulator-type = "pmic5-ldo";
		qcom,supported-modes =
			<RPMH_REGULATOR_MODE_LPM
			 RPMH_REGULATOR_MODE_HPM>;
		qcom,mode-threshold-currents = <0 10000>;

		L6M:
		pm8010m_l6: regulator-pm8010m-16 {
			regulator-name = "pm8010m_l6";
			qcom,set = <RPMH_REGULATOR_SET_ALL>;
			regulator-min-microvolt = <2700000>;
			regulator-max-microvolt = <2900000>;
			qcom,init-voltage = <2700000>;
			qcom,init-mode = <RPMH_REGULATOR_MODE_HPM>;
		};
	};

	rpmh-regulator-ldom7 {
		compatible = "qcom,rpmh-vrm-regulator";
		qcom,resource-name = "ldom7";
		qcom,regulator-type = "pmic5-ldo";
		qcom,supported-modes =
			<RPMH_REGULATOR_MODE_LPM
			 RPMH_REGULATOR_MODE_HPM>;
		qcom,mode-threshold-currents = <0 10000>;

		L7M:
		pm8010m_l7: regulator-pm8010m-17 {
			regulator-name = "pm8010m_l7";
			qcom,set = <RPMH_REGULATOR_SET_ALL>;
			regulator-min-microvolt = <2700000>;
			regulator-max-microvolt = <3000000>;
			qcom,init-voltage = <2700000>;
			qcom,init-mode = <RPMH_REGULATOR_MODE_HPM>;
		};
	};

	rpmh-regulator-ldon1 {
		compatible = "qcom,rpmh-vrm-regulator";
		qcom,resource-name = "ldon1";
		qcom,regulator-type = "pmic5-ldo";
		qcom,supported-modes =
			<RPMH_REGULATOR_MODE_LPM
			 RPMH_REGULATOR_MODE_HPM>;
		qcom,mode-threshold-currents = <0 30000>;

		L1N:
		pm8010n_l1: regulator-pm8010n-11 {
			regulator-name = "pm8010n_l1";
			qcom,set = <RPMH_REGULATOR_SET_ALL>;
			regulator-min-microvolt = <1050000>;
			regulator-max-microvolt = <1200000>;
			qcom,init-voltage = <1050000>;
			qcom,init-mode = <RPMH_REGULATOR_MODE_HPM>;
		};
	};

	rpmh-regulator-ldon2 {
		compatible = "qcom,rpmh-vrm-regulator";
		qcom,resource-name = "ldon2";
		qcom,regulator-type = "pmic5-ldo";
		qcom,supported-modes =
			<RPMH_REGULATOR_MODE_LPM
			 RPMH_REGULATOR_MODE_HPM>;
		qcom,mode-threshold-currents = <0 30000>;

		L2N:
		pm8010n_l2: regulator-pm8010n-12 {
			regulator-name = "pm8010n_l2";
			qcom,set = <RPMH_REGULATOR_SET_ALL>;
			regulator-min-microvolt = <950000>;
			regulator-max-microvolt = <1150000>;
			qcom,init-voltage = <950000>;
			qcom,init-mode = <RPMH_REGULATOR_MODE_HPM>;
		};
	};

	rpmh-regulator-ldon3 {
		compatible = "qcom,rpmh-vrm-regulator";
		qcom,resource-name = "ldon3";
		qcom,regulator-type = "pmic5-ldo";
		qcom,supported-modes =
			<RPMH_REGULATOR_MODE_LPM
			 RPMH_REGULATOR_MODE_HPM>;
		qcom,mode-threshold-currents = <0 10000>;

		L3N:
		pm8010n_l3: regulator-pm8010n-13 {
			regulator-name = "pm8010n_l3";
			qcom,set = <RPMH_REGULATOR_SET_ALL>;
			regulator-min-microvolt = <1792000>;
			regulator-max-microvolt = <1980000>;
			qcom,init-voltage = <1792000>;
			qcom,init-mode = <RPMH_REGULATOR_MODE_HPM>;
		};
	};

	rpmh-regulator-ldon4 {
		compatible = "qcom,rpmh-vrm-regulator";
		qcom,resource-name = "ldon4";
		qcom,regulator-type = "pmic5-ldo";
		qcom,supported-modes =
			<RPMH_REGULATOR_MODE_LPM
			 RPMH_REGULATOR_MODE_HPM>;
		qcom,mode-threshold-currents = <0 10000>;
		L4N:
		pm8010n_l4: regulator-pm8010n-14 {
			regulator-name = "pm8010n_l4";
			qcom,set = <RPMH_REGULATOR_SET_ALL>;
			regulator-min-microvolt = <1792000>;
			regulator-max-microvolt = <1900000>;
			qcom,init-voltage = <1792000>;
			qcom,init-mode = <RPMH_REGULATOR_MODE_HPM>;
		};
	};

	rpmh-regulator-ldon5 {
		compatible = "qcom,rpmh-vrm-regulator";
		qcom,resource-name = "ldon5";
		qcom,regulator-type = "pmic5-ldo";
		qcom,supported-modes =
			<RPMH_REGULATOR_MODE_LPM
			 RPMH_REGULATOR_MODE_HPM>;
		qcom,mode-threshold-currents = <0 10000>;

		L5N:
		pm8010n_l5: regulator-pm8010n-15 {
			regulator-name = "pm8010n_l5";
			qcom,set = <RPMH_REGULATOR_SET_ALL>;
			regulator-min-microvolt = <2700000>;
			regulator-max-microvolt = <2900000>;
			qcom,init-voltage = <2700000>;
			qcom,init-mode = <RPMH_REGULATOR_MODE_HPM>;
		};
	};

	rpmh-regulator-ldon7 {
		compatible = "qcom,rpmh-vrm-regulator";
		qcom,resource-name = "ldon7";
		qcom,regulator-type = "pmic5-ldo";
		qcom,supported-modes =
			<RPMH_REGULATOR_MODE_LPM
			 RPMH_REGULATOR_MODE_HPM>;
		qcom,mode-threshold-currents = <0 10000>;

		L7N:
		pm8010n_l7: regulator-pm8010n-17 {
			regulator-name = "pm8010n_l7";
			qcom,set = <RPMH_REGULATOR_SET_ALL>;
			regulator-min-microvolt = <2500000>;
			regulator-max-microvolt = <3300000>;
			qcom,init-voltage = <2500000>;
			qcom,init-mode = <RPMH_REGULATOR_MODE_HPM>;
		};
	};

};
